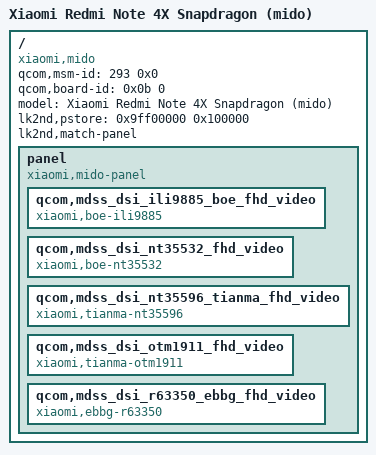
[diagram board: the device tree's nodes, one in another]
// SPDX-License-Identifier: GPL-2.0-only

/dts-v1/;

/include/ "msm8953.dtsi"

/ {
	// This is used by the bootloader to find the correct DTB 
	qcom,msm-id = <293 0x0>;
	qcom,board-id= <0x0b 0>;

	model = "Xiaomi Redmi Note 4X Snapdragon (mido)";
	compatible = "xiaomi,mido", "qcom,msm8953", "lk2nd,device";
	lk2nd,pstore = <0x9ff00000 0x100000>;
	lk2nd,match-panel;

	
	panel {
	
		compatible = "xiaomi,mido-panel";
		
		qcom,mdss_dsi_ili9885_boe_fhd_video{
			compatible = "xiaomi,boe-ili9885";
		};
		qcom,mdss_dsi_nt35532_fhd_video {
			compatible = "xiaomi,boe-nt35532";
		};
		qcom,mdss_dsi_nt35596_tianma_fhd_video{
			compatible = "xiaomi,tianma-nt35596";
		}; 
		qcom,mdss_dsi_otm1911_fhd_video{
			compatible = "xiaomi,tianma-otm1911";
		};
		qcom,mdss_dsi_r63350_ebbg_fhd_video{
			compatible = "xiaomi,ebbg-r63350";
		};
			
	};
};
